# S32K342_M7 register map
Vendor: NXP Semiconductors; File version: 1.5
CPU: CM7 r0p1, little endian, MPU, FPU, VTOR, 4 interrupt priority bits
Registers are 32-bit, read-write, reset 0x0 unless marked. A register's access mark holds for its fields unless they carry their own. Offsets are from the block's base; [hi:lo] are bit positions; 'fields as' and 'values as' point back to an identical list.

## WKPU
Base 0x402B4000
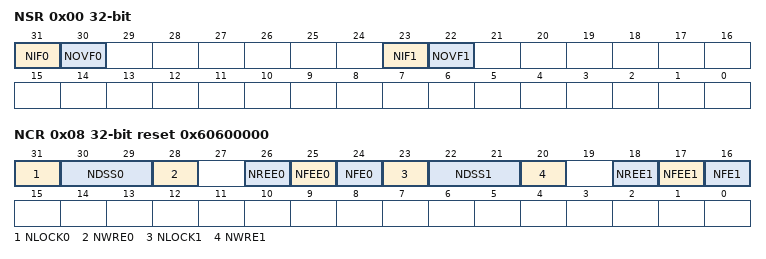
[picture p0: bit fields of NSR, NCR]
0x00 NSR write-1-clears — NMI Status Flag Register
  [31] NIF0 write-1-clears — NMI Status Flag 0
  [30] NOVF0 write-1-clears — NMI Overrun Status Flag 0
    0=No overrun has occurred on NMI input 0; 1=An overrun has occurred on NMI input 0
  [23] NIF1 write-1-clears — NMI Status Flag 1
    0=No event has occurred on the pad; 1=An event as defined by NREE1 and NFEE1 has occurred
  [22] NOVF1 write-1-clears — NMI Overrun Status Flag 1
    0=No overrun has occurred on NMI input 1; 1=An overrun has occurred on NMI input 1
0x08 NCR reset 0x60600000 — NMI Configuration Register
  [31] NLOCK0 — NMI Configuration Lock Register 0
  [30:29] NDSS0 — NMI Destination Source Select 0
    0=Non-maskable interrupt
  [28] NWRE0 — NMI Wakeup Request Enable 0
    0=System wakeup requests from the corresponding NIF0 field are disabled; 1=Causes a system wakeup request when NIF0 = 1 or NOVF0 = 1
  [26] NREE0 — NMI Rising-Edge Events Enable 0
    0=Rising-edge event is disabled; 1=Rising-edge event is enabled
  [25] NFEE0 — NMI Falling-edge Events Enable 0
  [24] NFE0 — NMI Filter Enable 0
    0=Filter is disabled; 1=Filter is enabled
  [23] NLOCK1 — NMI Configuration Lock Register 1
  [22:21] NDSS1 — NMI Destination Source Select 1
    0=Non-maskable interrupt
  [20] NWRE1 — NMI Wakeup Request Enable 1
    0=System wakeup requests from the corresponding NIF1 field are disabled; 1=Causes a system wakeup request when NIF1 = 1 or NOVF1 = 1
  [18] NREE1 — NMI Rising-Edge Events Enable 1
    values as NREE0
  [17] NFEE1 — NMI Falling-Edge Events Enable 1
  [16] NFE1 — NMI Filter Enable 1
    0=Filter is disabled; 1=Filter is enabled
0x14 WISR write-1-clears — Wakeup/Interrupt Status Flag Register
  [31:0] EIF write-1-clears — External Wakeup/Interrupt Status Flag x
0x18 IRER — Interrupt Request Enable Register
  [31:0] EIRE — External Interrupt Request Enable x
0x1C WRER — Wakeup Request Enable Register
  [31:0] WRE — External Wakeup Request Enable x
0x28 WIREER — Wakeup/Interrupt Rising-Edge Event Enable Register
  [31:0] IREE — External Interrupt Rising-edge Events Enable x
0x2C WIFEER — Wakeup/Interrupt Falling-Edge Event Enable Register
  [31:0] IFEEx — External Interrupt Falling-edge Events Enable x
0x30 WIFER — Wakeup/Interrupt Filter Enable Register
  [31:0] IFE — External Interrupt Filter Enable x
0x54 WISR_64 write-1-clears — Wakeup/Interrupt Status Flag Register
  [31:0] EIF_1 write-1-clears — External Wakeup/Interrupt Status Flag x
0x58 IRER_64 — Interrupt Request Enable Register
  [31:0] EIRE_1 — External Interrupt Request Enable x
0x5C WRER_64 — Wakeup Request Enable Register
  [31:0] WRE_1 — External Wakeup Request Enable x
0x68 WIREER_64 — Wakeup/Interrupt Rising-Edge Event Enable Register
  [31:0] IREE_1 — External Interrupt Rising-edge Events Enable x
0x6C WIFEER_64 — Wakeup/Interrupt Falling-Edge Event Enable Register
  [31:0] IFEEx_1 — External Interrupt Falling-edge Events Enable x
0x70 WIFER_64 — Wakeup/Interrupt Filter Enable Register
  [31:0] IFE_1 — External Interrupt Filter Enable x

## CMU_0 — CMU_FC
Base 0x402BC000
Same registers: CMU_3 0x402BC060, CMU_4 0x402BC080, CMU_5 0x402BC0A0
0x00 GCR — Global Configuration Register
  [0] FCE — Frequency Check Enable
    0=bfv_gcr_fce_0 (Stops frequency checking); 1=bfv_gcr_fce_1 (Starts frequency checking)
0x04 RCCR — Reference Count Configuration Register
  [15:0] REF_CNT — Reference clock count
0x08 HTCR reset 0xFFFFFF — High Threshold Configuration Register
  [23:0] HFREF — High frequency reference threshold
0x0C LTCR — Low Threshold Configuration Register
  [23:0] LFREF — Low Frequency Reference Threshold
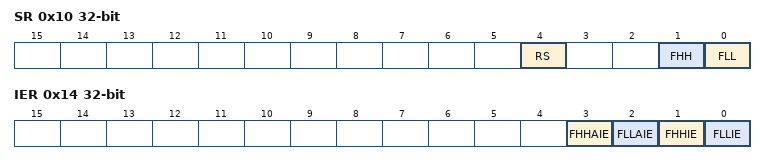
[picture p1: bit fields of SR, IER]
0x10 SR — Status Register
  [4] RS ro — Run Status
    0=bfv_sr_rs_0 (Frequency check stopped); 1=bfv_sr_rs_1 (Frequency check running)
  [1] FHH write-1-clears — Frequency higher than high frequency reference threshold event status
    0=bfv_sr_fhh_0 (No FHH event); 1=bfv_sr_fhh_1 (FHH event occurred)
  [0] FLL write-1-clears — Frequency lower than low frequency reference threshold event status
    0=bfv_sr_fll_0 (No FLL event); 1=bfv_sr_fll_1 (FLL event occurred)
0x14 IER — Interrupt Enable Register
  [3] FHHAIE — Frequency Higher than High Frequency Reference Threshold Asynchronous Interrupt Enable
    0=bfv_ier_fhhaie_0 (Asynchronous FHH event interrupt disabled); 1=bfv_ier_fhhaie_1 (Asynchronous FHH event interrupt enabled)
  [2] FLLAIE — Frequency Lower than Low Frequency Reference Threshold Asynchronous Interrupt Enable
    0=bfv_ier_fllaie_0 (Asynchronous FLL event interrupt disabled); 1=bfv_ier_fllaie_1 (Asynchronous FLL event interrupt enabled)
  [1] FHHIE — Frequency Higher than High Frequency Reference Threshold Synchronous Interrupt Enable
    0=bfv_ier_fhhie_0 (Synchronous FHH event interrupt disabled); 1=bfv_ier_fhhie_1 (Synchronous FHH event interrupt enabled)
  [0] FLLIE — Frequency Lower than Low Frequency Reference Threshold Synchronous Interrupt Enable
    0=bfv_ier_fllie_0 (Synchronous FLL event interrupt disabled); 1=bfv_ier_fllie_1 (Synchronous FLL event interrupt enabled)
